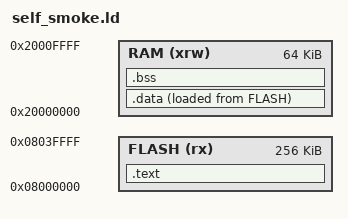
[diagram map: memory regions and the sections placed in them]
ENTRY(main)

MEMORY
{
  FLASH (rx)  : ORIGIN = 0x08000000, LENGTH = 256K
  RAM   (xrw) : ORIGIN = 0x20000000, LENGTH = 64K
}

_estack = ORIGIN(RAM) + LENGTH(RAM);

SECTIONS
{
  .text :
  {
    . = ALIGN(4);
    *(.text*)
    *(.rodata*)
    . = ALIGN(4);
    _etext = .;
  } > FLASH

  _sidata = LOADADDR(.data);
  .data :
  {
    . = ALIGN(4);
    _sdata = .;
    *(.data*)
    . = ALIGN(4);
    _edata = .;
  } > RAM AT> FLASH

  .bss (NOLOAD) :
  {
    . = ALIGN(4);
    _sbss = .;
    *(.bss*)
    *(COMMON)
    . = ALIGN(4);
    _ebss = .;
  } > RAM

  /DISCARD/ :
  {
    *(.comment*)
    *(.note*)
  }
}
